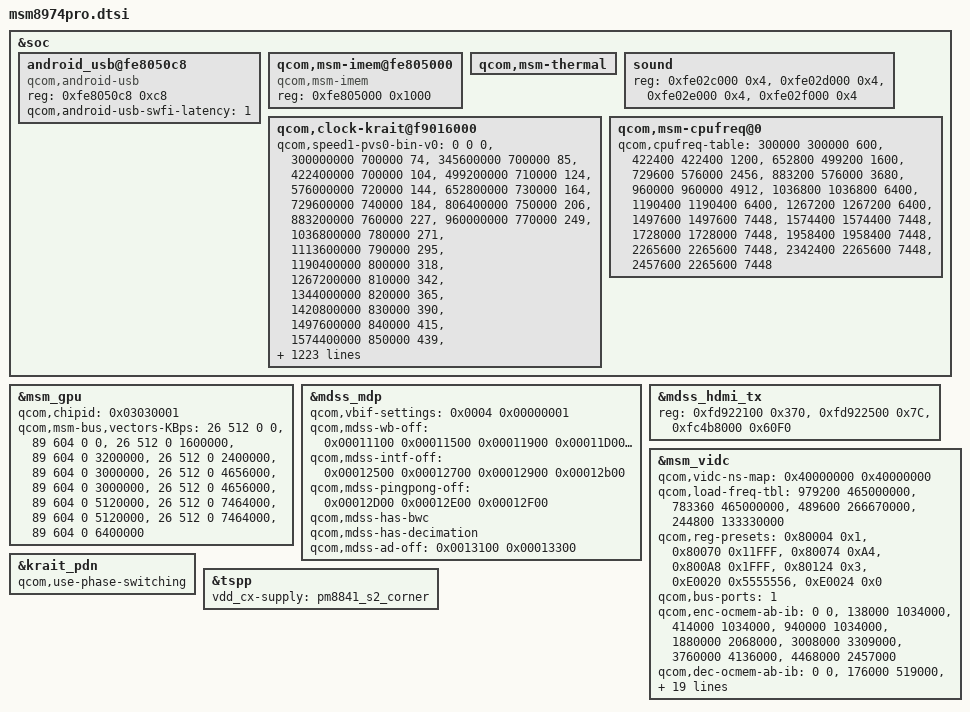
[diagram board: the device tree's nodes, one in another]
/* Copyright (c) 2013, The Linux Foundation. All rights reserved.
 *
 * This program is free software; you can redistribute it and/or modify
 * it under the terms of the GNU General Public License version 2 and
 * only version 2 as published by the Free Software Foundation.
 *
 * This program is distributed in the hope that it will be useful,
 * but WITHOUT ANY WARRANTY; without even the implied warranty of
 * MERCHANTABILITY or FITNESS FOR A PARTICULAR PURPOSE.  See the
 * GNU General Public License for more details.
 */

/*
 * As a general rule, only version-specific property overrides should be placed
 * inside this file. However, device definitions should be placed inside the
 * msm8974.dtsi file.
 */

/include/ "msm8974.dtsi"
/include/ "msm8974-v2-iommu.dtsi"
/include/ "msm8974-v2-iommu-domains.dtsi"
/include/ "msm8974-v2-pm.dtsi"

&soc {
	android_usb@fe8050c8 {
		compatible = "qcom,android-usb";
		reg = <0xfe8050c8 0xc8>;
		qcom,android-usb-swfi-latency = <1>;
	};

	qcom,msm-imem@fe805000 {
		compatible = "qcom,msm-imem";
		reg = <0xfe805000 0x1000>; /* Address and size of IMEM */
	};

	qcom,msm-thermal {
		/delete-property/ qcom,pmic-sw-mode-temp;
		/delete-property/ qcom,pmic-sw-mode-temp-hysteresis;
		/delete-property/ qcom,pmic-sw-mode-regs;
	};

	sound {
		reg = <0xfe02c000 0x4>,
		      <0xfe02d000 0x4>,
		      <0xfe02e000 0x4>,
		      <0xfe02f000 0x4>;
		reg-names = "lpaif_pri_mode_muxsel",
			    "lpaif_sec_mode_muxsel",
			    "lpaif_tert_mode_muxsel",
			    "lpaif_quat_mode_muxsel";
	};

	qcom,clock-krait@f9016000 {
		qcom,speed1-pvs0-bin-v0 =
			<          0       0    0 >,
			<  300000000  700000   74 >,
			<  345600000  700000   85 >,
			<  422400000  700000  104 >,
			<  499200000  710000  124 >,
			<  576000000  720000  144 >,
			<  652800000  730000  164 >,
			<  729600000  740000  184 >,
			<  806400000  750000  206 >,
			<  883200000  760000  227 >,
			<  960000000  770000  249 >,
			< 1036800000  780000  271 >,
			< 1113600000  790000  295 >,
			< 1190400000  800000  318 >,
			< 1267200000  810000  342 >,
			< 1344000000  820000  365 >,
			< 1420800000  830000  390 >,
			< 1497600000  840000  415 >,
			< 1574400000  850000  439 >,
			< 1651200000  865000  465 >,
			< 1728000000  880000  493 >,
			< 1804800000  895000  521 >,
			< 1881600000  910000  549 >,
			< 1958400000  925000  579 >,
			< 2035200000  940000  608 >,
			< 2112000000  955000  638 >,
			< 2150400000  970000  667 >,
			< 2188800000  970000  667 >,
			< 2265600000  980000  700 >,
			< 2342400000  990000  734 >,
			< 2419200000 1015000  769 >,
			< 2457600000 1020000  785 >;

		qcom,speed1-pvs1-bin-v0 =
			<          0       0    0 >,
			<  300000000  700000   74 >,
			<  345600000  700000   85 >,
			<  422400000  700000  104 >,
			<  499200000  710000  124 >,
			<  576000000  720000  144 >,
			<  652800000  730000  164 >,
			<  729600000  740000  184 >,
			<  806400000  750000  206 >,
			<  883200000  760000  227 >,
			<  960000000  770000  249 >,
			< 1036800000  780000  271 >,
			< 1113600000  790000  295 >,
			< 1190400000  800000  318 >,
			< 1267200000  810000  342 >,
			< 1344000000  820000  365 >,
			< 1420800000  830000  390 >,
			< 1497600000  840000  415 >,
			< 1574400000  850000  439 >,
			< 1651200000  865000  465 >,
			< 1728000000  880000  493 >,
			< 1804800000  895000  521 >,
			< 1881600000  910000  549 >,
			< 1958400000  925000  579 >,
			< 2035200000  940000  608 >,
			< 2112000000  955000  638 >,
			< 2150400000  970000  667 >,
			< 2188800000  970000  667 >,
			< 2265600000  980000  700 >,
			< 2342400000  990000  734 >,
			< 2419200000 1015000  769 >,
			< 2457600000 1020000  785 >;

		qcom,speed1-pvs2-bin-v0 =
			<          0       0    0 >,
			<  300000000  700000   74 >,
			<  345600000  700000   85 >,
			<  422400000  700000  104 >,
			<  499200000  710000  124 >,
			<  576000000  720000  144 >,
			<  652800000  730000  164 >,
			<  729600000  740000  184 >,
			<  806400000  750000  206 >,
			<  883200000  760000  227 >,
			<  960000000  770000  249 >,
			< 1036800000  780000  271 >,
			< 1113600000  790000  295 >,
			< 1190400000  800000  318 >,
			< 1267200000  810000  342 >,
			< 1344000000  820000  365 >,
			< 1420800000  830000  390 >,
			< 1497600000  840000  415 >,
			< 1574400000  850000  439 >,
			< 1651200000  865000  465 >,
			< 1728000000  880000  493 >,
			< 1804800000  895000  521 >,
			< 1881600000  910000  549 >,
			< 1958400000  925000  579 >,
			< 2035200000  940000  608 >,
			< 2112000000  955000  638 >,
			< 2150400000  970000  667 >,
			< 2188800000  970000  667 >,
			< 2265600000  980000  700 >,
			< 2342400000  990000  734 >,
			< 2419200000 1015000  769 >,
			< 2457600000 1020000  785 >;

		qcom,speed1-pvs3-bin-v0 =
			<          0       0    0 >,
			<  300000000  700000   74 >,
			<  345600000  700000   85 >,
			<  422400000  700000  104 >,
			<  499200000  710000  124 >,
			<  576000000  720000  144 >,
			<  652800000  730000  164 >,
			<  729600000  740000  184 >,
			<  806400000  750000  206 >,
			<  883200000  760000  227 >,
			<  960000000  770000  249 >,
			< 1036800000  780000  271 >,
			< 1113600000  790000  295 >,
			< 1190400000  800000  318 >,
			< 1267200000  810000  342 >,
			< 1344000000  820000  365 >,
			< 1420800000  830000  390 >,
			< 1497600000  840000  415 >,
			< 1574400000  850000  439 >,
			< 1651200000  865000  465 >,
			< 1728000000  880000  493 >,
			< 1804800000  895000  521 >,
			< 1881600000  910000  549 >,
			< 1958400000  925000  579 >,
			< 2035200000  940000  608 >,
			< 2112000000  955000  638 >,
			< 2150400000  970000  667 >,
			< 2188800000  970000  667 >,
			< 2265600000  980000  700 >,
			< 2342400000  990000  734 >,
			< 2419200000 1015000  769 >,
			< 2457600000 1020000  785 >;

		qcom,speed1-pvs4-bin-v0 =
			<          0       0    0 >,
			<  300000000  700000   74 >,
			<  345600000  700000   85 >,
			<  422400000  700000  104 >,
			<  499200000  710000  124 >,
			<  576000000  720000  144 >,
			<  652800000  730000  164 >,
			<  729600000  740000  184 >,
			<  806400000  750000  206 >,
			<  883200000  760000  227 >,
			<  960000000  770000  249 >,
			< 1036800000  780000  271 >,
			< 1113600000  790000  295 >,
			< 1190400000  800000  318 >,
			< 1267200000  810000  342 >,
			< 1344000000  820000  365 >,
			< 1420800000  830000  390 >,
			< 1497600000  840000  415 >,
			< 1574400000  850000  439 >,
			< 1651200000  865000  465 >,
			< 1728000000  880000  493 >,
			< 1804800000  895000  521 >,
			< 1881600000  910000  549 >,
			< 1958400000  925000  579 >,
			< 2035200000  940000  608 >,
			< 2112000000  955000  638 >,
			< 2150400000  970000  667 >,
			< 2188800000  970000  667 >,
			< 2265600000  980000  700 >,
			< 2342400000  990000  734 >,
			< 2419200000 1015000  769 >,
			< 2457600000 1020000  785 >;

		qcom,speed1-pvs5-bin-v0 =
			<          0       0    0 >,
			<  300000000  700000   74 >,
			<  345600000  700000   85 >,
			<  422400000  700000  104 >,
			<  499200000  710000  124 >,
			<  576000000  720000  144 >,
			<  652800000  730000  164 >,
			<  729600000  740000  184 >,
			<  806400000  750000  206 >,
			<  883200000  760000  227 >,
			<  960000000  770000  249 >,
			< 1036800000  780000  271 >,
			< 1113600000  790000  295 >,
			< 1190400000  800000  318 >,
			< 1267200000  810000  342 >,
			< 1344000000  820000  365 >,
			< 1420800000  830000  390 >,
			< 1497600000  840000  415 >,
			< 1574400000  850000  439 >,
			< 1651200000  865000  465 >,
			< 1728000000  880000  493 >,
			< 1804800000  895000  521 >,
			< 1881600000  910000  549 >,
			< 1958400000  925000  579 >,
			< 2035200000  940000  608 >,
			< 2112000000  955000  638 >,
			< 2150400000  970000  667 >,
			< 2188800000  970000  667 >,
			< 2265600000  980000  700 >,
			< 2342400000  990000  734 >,
			< 2419200000 1015000  769 >,
			< 2457600000 1020000  785 >;

		qcom,speed1-pvs6-bin-v0 =
			<          0       0    0 >,
			<  300000000  700000   74 >,
			<  345600000  700000   85 >,
			<  422400000  700000  104 >,
			<  499200000  710000  124 >,
			<  576000000  720000  144 >,
			<  652800000  730000  164 >,
			<  729600000  740000  184 >,
			<  806400000  750000  206 >,
			<  883200000  760000  227 >,
			<  960000000  770000  249 >,
			< 1036800000  780000  271 >,
			< 1113600000  790000  295 >,
			< 1190400000  800000  318 >,
			< 1267200000  810000  342 >,
			< 1344000000  820000  365 >,
			< 1420800000  830000  390 >,
			< 1497600000  840000  415 >,
			< 1574400000  850000  439 >,
			< 1651200000  865000  465 >,
			< 1728000000  880000  493 >,
			< 1804800000  895000  521 >,
			< 1881600000  910000  549 >,
			< 1958400000  925000  579 >,
			< 2035200000  940000  608 >,
			< 2112000000  955000  638 >,
			< 2150400000  970000  667 >,
			< 2188800000  970000  667 >,
			< 2265600000  980000  700 >,
			< 2342400000  990000  734 >,
			< 2419200000 1015000  769 >,
			< 2457600000 1020000  785 >;

		qcom,speed3-pvs0-bin-v0 =
			<          0       0    0 >,
			<  300000000  800000   76 >,
			<  345600000  800000   87 >,
			<  422400000  800000  106 >,
			<  499200000  800000  125 >,
			<  576000000  800000  145 >,
			<  652800000  810000  165 >,
			<  729600000  820000  186 >,
			<  806400000  830000  208 >,
			<  883200000  840000  229 >,
			<  960000000  850000  251 >,
			< 1036800000  860000  273 >,
			< 1113600000  870000  296 >,
			< 1190400000  880000  319 >,
			< 1267200000  890000  342 >,
			< 1344000000  900000  365 >,
			< 1420800000  910000  390 >,
			< 1497600000  920000  415 >,
			< 1574400000  930000  439 >,
			< 1651200000  945000  465 >,
			< 1728000000  960000  493 >,
			< 1804800000  975000  521 >,
			< 1881600000  990000  549 >,
			< 1958400000 1005000  579 >,
			< 2035200000 1020000  608 >,
			< 2112000000 1035000  638 >,
			< 2150400000 1050000  667 >,
			< 2188800000 1050000  667 >,
			< 2265600000 1065000  700 >,
			< 2342400000 1080000  734 >,
			< 2419200000 1095000  769 >,
			< 2457600000 1100000  785 >;

		qcom,speed3-pvs1-bin-v0 =
			<          0       0    0 >,
			<  300000000  800000   76 >,
			<  345600000  800000   87 >,
			<  422400000  800000  106 >,
			<  499200000  800000  125 >,
			<  576000000  800000  145 >,
			<  652800000  800000  165 >,
			<  729600000  800000  186 >,
			<  806400000  805000  208 >,
			<  883200000  815000  229 >,
			<  960000000  825000  251 >,
			< 1036800000  835000  273 >,
			< 1113600000  845000  296 >,
			< 1190400000  855000  319 >,
			< 1267200000  865000  342 >,
			< 1344000000  875000  365 >,
			< 1420800000  885000  390 >,
			< 1497600000  895000  415 >,
			< 1574400000  905000  439 >,
			< 1651200000  920000  465 >,
			< 1728000000  935000  493 >,
			< 1804800000  950000  521 >,
			< 1881600000  965000  549 >,
			< 1958400000  980000  579 >,
			< 2035200000  995000  608 >,
			< 2112000000 1010000  638 >,
			< 2150400000 1025000  667 >,
			< 2188800000 1025000  667 >,
			< 2265600000 1040000  700 >,
			< 2342400000 1055000  734 >,
			< 2419200000 1070000  769 >,
			< 2457600000 1075000  785 >;

		qcom,speed3-pvs2-bin-v0 =
			<          0       0    0 >,
			<  300000000  775000   76 >,
			<  345600000  775000   87 >,
			<  422400000  775000  106 >,
			<  499200000  775000  125 >,
			<  576000000  775000  145 >,
			<  652800000  775000  165 >,
			<  729600000  775000  186 >,
			<  806400000  780000  208 >,
			<  883200000  790000  229 >,
			<  960000000  800000  251 >,
			< 1036800000  810000  273 >,
			< 1113600000  820000  296 >,
			< 1190400000  830000  319 >,
			< 1267200000  840000  342 >,
			< 1344000000  850000  365 >,
			< 1420800000  860000  390 >,
			< 1497600000  870000  415 >,
			< 1574400000  880000  439 >,
			< 1651200000  895000  465 >,
			< 1728000000  910000  493 >,
			< 1804800000  925000  521 >,
			< 1881600000  940000  549 >,
			< 1958400000  955000  579 >,
			< 2035200000  970000  608 >,
			< 2112000000  985000  638 >,
			< 2150400000 1000000  667 >,
			< 2188800000 1000000  667 >,
			< 2265600000 1015000  700 >,
			< 2342400000 1030000  734 >,
			< 2419200000 1045000  769 >,
			< 2457600000 1050000  785 >;

		qcom,speed3-pvs3-bin-v0 =
			<          0       0    0 >,
			<  300000000  775000   76 >,
			<  345600000  775000   87 >,
			<  422400000  775000  106 >,
			<  499200000  775000  125 >,
			<  576000000  775000  145 >,
			<  652800000  775000  165 >,
			<  729600000  775000  186 >,
			<  806400000  775000  208 >,
			<  883200000  775000  229 >,
			<  960000000  780000  251 >,
			< 1036800000  785000  273 >,
			< 1113600000  795000  296 >,
			< 1190400000  805000  319 >,
			< 1267200000  815000  342 >,
			< 1344000000  825000  365 >,
			< 1420800000  835000  390 >,
			< 1497600000  845000  415 >,
			< 1574400000  855000  439 >,
			< 1651200000  870000  465 >,
			< 1728000000  885000  493 >,
			< 1804800000  900000  521 >,
			< 1881600000  915000  549 >,
			< 1958400000  930000  579 >,
			< 2035200000  945000  608 >,
			< 2112000000  960000  638 >,
			< 2150400000  975000  667 >,
			< 2188800000  975000  667 >,
			< 2265600000  990000  700 >,
			< 2342400000 1005000  734 >,
			< 2419200000 1020000  769 >,
			< 2457600000 1025000  785 >;

		qcom,speed3-pvs4-bin-v0 =
			<          0       0    0 >,
			<  300000000  775000   76 >,
			<  345600000  775000   87 >,
			<  422400000  775000  106 >,
			<  499200000  775000  125 >,
			<  576000000  775000  145 >,
			<  652800000  775000  165 >,
			<  729600000  775000  186 >,
			<  806400000  775000  208 >,
			<  883200000  775000  229 >,
			<  960000000  775000  251 >,
			< 1036800000  775000  273 >,
			< 1113600000  775000  296 >,
			< 1190400000  780000  319 >,
			< 1267200000  790000  342 >,
			< 1344000000  800000  365 >,
			< 1420800000  810000  390 >,
			< 1497600000  820000  415 >,
			< 1574400000  830000  439 >,
			< 1651200000  845000  465 >,
			< 1728000000  860000  493 >,
			< 1804800000  875000  521 >,
			< 1881600000  890000  549 >,
			< 1958400000  905000  579 >,
			< 2035200000  920000  608 >,
			< 2112000000  935000  638 >,
			< 2150400000  950000  667 >,
			< 2188800000  950000  667 >,
			< 2265600000  965000  700 >,
			< 2342400000  980000  734 >,
			< 2419200000  995000  769 >,
			< 2457600000 1000000  785 >;

		qcom,speed3-pvs5-bin-v0 =
			<          0       0    0 >,
			<  300000000  750000   76 >,
			<  345600000  750000   87 >,
			<  422400000  750000  106 >,
			<  499200000  750000  125 >,
			<  576000000  750000  145 >,
			<  652800000  750000  165 >,
			<  729600000  750000  186 >,
			<  806400000  750000  208 >,
			<  883200000  750000  229 >,
			<  960000000  750000  251 >,
			< 1036800000  750000  273 >,
			< 1113600000  750000  296 >,
			< 1190400000  760000  319 >,
			< 1267200000  770000  342 >,
			< 1344000000  780000  365 >,
			< 1420800000  790000  390 >,
			< 1497600000  800000  415 >,
			< 1574400000  810000  439 >,
			< 1651200000  820000  465 >,
			< 1728000000  835000  493 >,
			< 1804800000  850000  521 >,
			< 1881600000  865000  549 >,
			< 1958400000  880000  579 >,
			< 2035200000  895000  608 >,
			< 2112000000  910000  638 >,
			< 2150400000  925000  667 >,
			< 2188800000  925000  667 >,
			< 2265600000  940000  700 >,
			< 2342400000  955000  734 >,
			< 2419200000  970000  769 >,
			< 2457600000  975000  785 >;

		qcom,speed3-pvs6-bin-v0 =
			<          0       0    0 >,
			<  300000000  750000   76 >,
			<  345600000  750000   87 >,
			<  422400000  750000  106 >,
			<  499200000  750000  125 >,
			<  576000000  750000  145 >,
			<  652800000  750000  165 >,
			<  729600000  750000  186 >,
			<  806400000  750000  208 >,
			<  883200000  750000  229 >,
			<  960000000  750000  251 >,
			< 1036800000  750000  273 >,
			< 1113600000  750000  296 >,
			< 1190400000  750000  319 >,
			< 1267200000  755000  342 >,
			< 1344000000  765000  365 >,
			< 1420800000  775000  390 >,
			< 1497600000  785000  415 >,
			< 1574400000  795000  439 >,
			< 1651200000  805000  465 >,
			< 1728000000  815000  493 >,
			< 1804800000  825000  521 >,
			< 1881600000  840000  549 >,
			< 1958400000  855000  579 >,
			< 2035200000  870000  608 >,
			< 2112000000  885000  638 >,
			< 2150400000  900000  667 >,
			< 2188800000  900000  667 >,
			< 2265600000  915000  700 >,
			< 2342400000  930000  734 >,
			< 2419200000  945000  769 >,
			< 2457600000  950000  785 >;

		qcom,speed1-pvs0-bin-v1 =
			<          0       0    0 >,
			<  300000000  700000   74 >,
			<  345600000  700000   85 >,
			<  422400000  700000  104 >,
			<  499200000  710000  124 >,
			<  576000000  720000  144 >,
			<  652800000  730000  164 >,
			<  729600000  740000  184 >,
			<  806400000  750000  206 >,
			<  883200000  760000  227 >,
			<  960000000  770000  249 >,
			< 1036800000  780000  271 >,
			< 1113600000  790000  295 >,
			< 1190400000  800000  318 >,
			< 1267200000  810000  342 >,
			< 1344000000  820000  365 >,
			< 1420800000  830000  390 >,
			< 1497600000  840000  415 >,
			< 1574400000  850000  439 >,
			< 1651200000  865000  465 >,
			< 1728000000  880000  493 >,
			< 1804800000  895000  521 >,
			< 1881600000  910000  549 >,
			< 1958400000  925000  579 >,
			< 2035200000  940000  608 >,
			< 2112000000  955000  638 >,
			< 2150400000  970000  667 >,
			< 2188800000  970000  667 >,
			< 2265600000  980000  700 >,
			< 2342400000  990000  734 >,
			< 2419200000 1015000  769 >,
			< 2457600000 1020000  785 >;

		qcom,speed1-pvs1-bin-v1 =
			<          0       0    0 >,
			<  300000000  700000   74 >,
			<  345600000  700000   85 >,
			<  422400000  700000  104 >,
			<  499200000  710000  124 >,
			<  576000000  720000  144 >,
			<  652800000  730000  164 >,
			<  729600000  740000  184 >,
			<  806400000  750000  206 >,
			<  883200000  760000  227 >,
			<  960000000  770000  249 >,
			< 1036800000  780000  271 >,
			< 1113600000  790000  295 >,
			< 1190400000  800000  318 >,
			< 1267200000  810000  342 >,
			< 1344000000  820000  365 >,
			< 1420800000  830000  390 >,
			< 1497600000  840000  415 >,
			< 1574400000  850000  439 >,
			< 1651200000  865000  465 >,
			< 1728000000  880000  493 >,
			< 1804800000  895000  521 >,
			< 1881600000  910000  549 >,
			< 1958400000  925000  579 >,
			< 2035200000  940000  608 >,
			< 2112000000  955000  638 >,
			< 2150400000  970000  667 >,
			< 2188800000  970000  667 >,
			< 2265600000  980000  700 >,
			< 2342400000  990000  734 >,
			< 2419200000 1015000  769 >,
			< 2457600000 1020000  785 >;

		qcom,speed1-pvs2-bin-v1 =
			<          0       0    0 >,
			<  300000000  700000   74 >,
			<  345600000  700000   85 >,
			<  422400000  700000  104 >,
			<  499200000  710000  124 >,
			<  576000000  720000  144 >,
			<  652800000  730000  164 >,
			<  729600000  740000  184 >,
			<  806400000  750000  206 >,
			<  883200000  760000  227 >,
			<  960000000  770000  249 >,
			< 1036800000  780000  271 >,
			< 1113600000  790000  295 >,
			< 1190400000  800000  318 >,
			< 1267200000  810000  342 >,
			< 1344000000  820000  365 >,
			< 1420800000  830000  390 >,
			< 1497600000  840000  415 >,
			< 1574400000  850000  439 >,
			< 1651200000  865000  465 >,
			< 1728000000  880000  493 >,
			< 1804800000  895000  521 >,
			< 1881600000  910000  549 >,
			< 1958400000  925000  579 >,
			< 2035200000  940000  608 >,
			< 2112000000  955000  638 >,
			< 2150400000  970000  667 >,
			< 2188800000  970000  667 >,
			< 2265600000  980000  700 >,
			< 2342400000  990000  734 >,
			< 2419200000 1015000  769 >,
			< 2457600000 1020000  785 >;

		qcom,speed1-pvs3-bin-v1 =
			<          0       0    0 >,
			<  300000000  700000   74 >,
			<  345600000  700000   85 >,
			<  422400000  700000  104 >,
			<  499200000  710000  124 >,
			<  576000000  720000  144 >,
			<  652800000  730000  164 >,
			<  729600000  740000  184 >,
			<  806400000  750000  206 >,
			<  883200000  760000  227 >,
			<  960000000  770000  249 >,
			< 1036800000  780000  271 >,
			< 1113600000  790000  295 >,
			< 1190400000  800000  318 >,
			< 1267200000  810000  342 >,
			< 1344000000  820000  365 >,
			< 1420800000  830000  390 >,
			< 1497600000  840000  415 >,
			< 1574400000  850000  439 >,
			< 1651200000  865000  465 >,
			< 1728000000  880000  493 >,
			< 1804800000  895000  521 >,
			< 1881600000  910000  549 >,
			< 1958400000  925000  579 >,
			< 2035200000  940000  608 >,
			< 2112000000  955000  638 >,
			< 2150400000  970000  667 >,
			< 2188800000  970000  667 >,
			< 2265600000  980000  700 >,
			< 2342400000  990000  734 >,
			< 2419200000 1015000  769 >,
			< 2457600000 1020000  785 >;

		qcom,speed1-pvs4-bin-v1 =
			<          0       0    0 >,
			<  300000000  700000   74 >,
			<  345600000  700000   85 >,
			<  422400000  700000  104 >,
			<  499200000  710000  124 >,
			<  576000000  720000  144 >,
			<  652800000  730000  164 >,
			<  729600000  740000  184 >,
			<  806400000  750000  206 >,
			<  883200000  760000  227 >,
			<  960000000  770000  249 >,
			< 1036800000  780000  271 >,
			< 1113600000  790000  295 >,
			< 1190400000  800000  318 >,
			< 1267200000  810000  342 >,
			< 1344000000  820000  365 >,
			< 1420800000  830000  390 >,
			< 1497600000  840000  415 >,
			< 1574400000  850000  439 >,
			< 1651200000  865000  465 >,
			< 1728000000  880000  493 >,
			< 1804800000  895000  521 >,
			< 1881600000  910000  549 >,
			< 1958400000  925000  579 >,
			< 2035200000  940000  608 >,
			< 2112000000  955000  638 >,
			< 2150400000  970000  667 >,
			< 2188800000  970000  667 >,
			< 2265600000  980000  700 >,
			< 2342400000  990000  734 >,
			< 2419200000 1015000  769 >,
			< 2457600000 1020000  785 >;

		qcom,speed1-pvs5-bin-v1 =
			<          0       0    0 >,
			<  300000000  700000   74 >,
			<  345600000  700000   85 >,
			<  422400000  700000  104 >,
			<  499200000  710000  124 >,
			<  576000000  720000  144 >,
			<  652800000  730000  164 >,
			<  729600000  740000  184 >,
			<  806400000  750000  206 >,
			<  883200000  760000  227 >,
			<  960000000  770000  249 >,
			< 1036800000  780000  271 >,
			< 1113600000  790000  295 >,
			< 1190400000  800000  318 >,
			< 1267200000  810000  342 >,
			< 1344000000  820000  365 >,
			< 1420800000  830000  390 >,
			< 1497600000  840000  415 >,
			< 1574400000  850000  439 >,
			< 1651200000  865000  465 >,
			< 1728000000  880000  493 >,
			< 1804800000  895000  521 >,
			< 1881600000  910000  549 >,
			< 1958400000  925000  579 >,
			< 2035200000  940000  608 >,
			< 2112000000  955000  638 >,
			< 2150400000  970000  667 >,
			< 2188800000  970000  667 >,
			< 2265600000  980000  700 >,
			< 2342400000  990000  734 >,
			< 2419200000 1015000  769 >,
			< 2457600000 1020000  785 >;

		qcom,speed1-pvs6-bin-v1 =
			<          0       0    0 >,
			<  300000000  700000   74 >,
			<  345600000  700000   85 >,
			<  422400000  700000  104 >,
			<  499200000  710000  124 >,
			<  576000000  720000  144 >,
			<  652800000  730000  164 >,
			<  729600000  740000  184 >,
			<  806400000  750000  206 >,
			<  883200000  760000  227 >,
			<  960000000  770000  249 >,
			< 1036800000  780000  271 >,
			< 1113600000  790000  295 >,
			< 1190400000  800000  318 >,
			< 1267200000  810000  342 >,
			< 1344000000  820000  365 >,
			< 1420800000  830000  390 >,
			< 1497600000  840000  415 >,
			< 1574400000  850000  439 >,
			< 1651200000  865000  465 >,
			< 1728000000  880000  493 >,
			< 1804800000  895000  521 >,
			< 1881600000  910000  549 >,
			< 1958400000  925000  579 >,
			< 2035200000  940000  608 >,
			< 2112000000  955000  638 >,
			< 2150400000  970000  667 >,
			< 2188800000  970000  667 >,
			< 2265600000  980000  700 >,
			< 2342400000  990000  734 >,
			< 2419200000 1015000  769 >,
			< 2457600000 1020000  785 >;

		qcom,speed1-pvs7-bin-v1 =
			<          0       0    0 >,
			<  300000000  700000   74 >,
			<  345600000  700000   85 >,
			<  422400000  700000  104 >,
			<  499200000  710000  124 >,
			<  576000000  720000  144 >,
			<  652800000  730000  164 >,
			<  729600000  740000  184 >,
			<  806400000  750000  206 >,
			<  883200000  760000  227 >,
			<  960000000  770000  249 >,
			< 1036800000  780000  271 >,
			< 1113600000  790000  295 >,
			< 1190400000  800000  318 >,
			< 1267200000  810000  342 >,
			< 1344000000  820000  365 >,
			< 1420800000  830000  390 >,
			< 1497600000  840000  415 >,
			< 1574400000  850000  439 >,
			< 1651200000  865000  465 >,
			< 1728000000  880000  493 >,
			< 1804800000  895000  521 >,
			< 1881600000  910000  549 >,
			< 1958400000  925000  579 >,
			< 2035200000  940000  608 >,
			< 2112000000  955000  638 >,
			< 2150400000  970000  667 >,
			< 2188800000  970000  667 >,
			< 2265600000  980000  700 >,
			< 2342400000  990000  734 >,
			< 2419200000 1015000  769 >,
			< 2457600000 1020000  785 >;

		qcom,speed1-pvs8-bin-v1 =
			<          0       0    0 >,
			<  300000000  700000   74 >,
			<  345600000  700000   85 >,
			<  422400000  700000  104 >,
			<  499200000  710000  124 >,
			<  576000000  720000  144 >,
			<  652800000  730000  164 >,
			<  729600000  740000  184 >,
			<  806400000  750000  206 >,
			<  883200000  760000  227 >,
			<  960000000  770000  249 >,
			< 1036800000  780000  271 >,
			< 1113600000  790000  295 >,
			< 1190400000  800000  318 >,
			< 1267200000  810000  342 >,
			< 1344000000  820000  365 >,
			< 1420800000  830000  390 >,
			< 1497600000  840000  415 >,
			< 1574400000  850000  439 >,
			< 1651200000  865000  465 >,
			< 1728000000  880000  493 >,
			< 1804800000  895000  521 >,
			< 1881600000  910000  549 >,
			< 1958400000  925000  579 >,
			< 2035200000  940000  608 >,
			< 2112000000  955000  638 >,
			< 2150400000  970000  667 >,
			< 2188800000  970000  667 >,
			< 2265600000  980000  700 >,
			< 2342400000  990000  734 >,
			< 2419200000 1015000  769 >,
			< 2457600000 1020000  785 >;

		qcom,speed1-pvs9-bin-v1 =
			<          0       0    0 >,
			<  300000000  700000   74 >,
			<  345600000  700000   85 >,
			<  422400000  700000  104 >,
			<  499200000  710000  124 >,
			<  576000000  720000  144 >,
			<  652800000  730000  164 >,
			<  729600000  740000  184 >,
			<  806400000  750000  206 >,
			<  883200000  760000  227 >,
			<  960000000  770000  249 >,
			< 1036800000  780000  271 >,
			< 1113600000  790000  295 >,
			< 1190400000  800000  318 >,
			< 1267200000  810000  342 >,
			< 1344000000  820000  365 >,
			< 1420800000  830000  390 >,
			< 1497600000  840000  415 >,
			< 1574400000  850000  439 >,
			< 1651200000  865000  465 >,
			< 1728000000  880000  493 >,
			< 1804800000  895000  521 >,
			< 1881600000  910000  549 >,
			< 1958400000  925000  579 >,
			< 2035200000  940000  608 >,
			< 2112000000  955000  638 >,
			< 2150400000  970000  667 >,
			< 2188800000  970000  667 >,
			< 2265600000  980000  700 >,
			< 2342400000  990000  734 >,
			< 2419200000 1015000  769 >,
			< 2457600000 1020000  785 >;

		qcom,speed1-pvs10-bin-v1 =
			<          0       0    0 >,
			<  300000000  700000   74 >,
			<  345600000  700000   85 >,
			<  422400000  700000  104 >,
			<  499200000  710000  124 >,
			<  576000000  720000  144 >,
			<  652800000  730000  164 >,
			<  729600000  740000  184 >,
			<  806400000  750000  206 >,
			<  883200000  760000  227 >,
			<  960000000  770000  249 >,
			< 1036800000  780000  271 >,
			< 1113600000  790000  295 >,
			< 1190400000  800000  318 >,
			< 1267200000  810000  342 >,
			< 1344000000  820000  365 >,
			< 1420800000  830000  390 >,
			< 1497600000  840000  415 >,
			< 1574400000  850000  439 >,
			< 1651200000  865000  465 >,
			< 1728000000  880000  493 >,
			< 1804800000  895000  521 >,
			< 1881600000  910000  549 >,
			< 1958400000  925000  579 >,
			< 2035200000  940000  608 >,
			< 2112000000  955000  638 >,
			< 2150400000  970000  667 >,
			< 2188800000  970000  667 >,
			< 2265600000  980000  700 >,
			< 2342400000  990000  734 >,
			< 2419200000 1015000  769 >,
			< 2457600000 1020000  785 >;

		qcom,speed1-pvs11-bin-v1 =
			<          0       0    0 >,
			<  300000000  700000   74 >,
			<  345600000  700000   85 >,
			<  422400000  700000  104 >,
			<  499200000  710000  124 >,
			<  576000000  720000  144 >,
			<  652800000  730000  164 >,
			<  729600000  740000  184 >,
			<  806400000  750000  206 >,
			<  883200000  760000  227 >,
			<  960000000  770000  249 >,
			< 1036800000  780000  271 >,
			< 1113600000  790000  295 >,
			< 1190400000  800000  318 >,
			< 1267200000  810000  342 >,
			< 1344000000  820000  365 >,
			< 1420800000  830000  390 >,
			< 1497600000  840000  415 >,
			< 1574400000  850000  439 >,
			< 1651200000  865000  465 >,
			< 1728000000  880000  493 >,
			< 1804800000  895000  521 >,
			< 1881600000  910000  549 >,
			< 1958400000  925000  579 >,
			< 2035200000  940000  608 >,
			< 2112000000  955000  638 >,
			< 2150400000  970000  667 >,
			< 2188800000  970000  667 >,
			< 2265600000  980000  700 >,
			< 2342400000  990000  734 >,
			< 2419200000 1015000  769 >,
			< 2457600000 1020000  785 >;

		qcom,speed1-pvs12-bin-v1 =
			<          0       0    0 >,
			<  300000000  700000   74 >,
			<  345600000  700000   85 >,
			<  422400000  700000  104 >,
			<  499200000  710000  124 >,
			<  576000000  720000  144 >,
			<  652800000  730000  164 >,
			<  729600000  740000  184 >,
			<  806400000  750000  206 >,
			<  883200000  760000  227 >,
			<  960000000  770000  249 >,
			< 1036800000  780000  271 >,
			< 1113600000  790000  295 >,
			< 1190400000  800000  318 >,
			< 1267200000  810000  342 >,
			< 1344000000  820000  365 >,
			< 1420800000  830000  390 >,
			< 1497600000  840000  415 >,
			< 1574400000  850000  439 >,
			< 1651200000  865000  465 >,
			< 1728000000  880000  493 >,
			< 1804800000  895000  521 >,
			< 1881600000  910000  549 >,
			< 1958400000  925000  579 >,
			< 2035200000  940000  608 >,
			< 2112000000  955000  638 >,
			< 2150400000  970000  667 >,
			< 2188800000  970000  667 >,
			< 2265600000  980000  700 >,
			< 2342400000  990000  734 >,
			< 2419200000 1015000  769 >,
			< 2457600000 1020000  785 >;

		qcom,speed1-pvs13-bin-v1 =
			<          0       0    0 >,
			<  300000000  700000   74 >,
			<  345600000  700000   85 >,
			<  422400000  700000  104 >,
			<  499200000  710000  124 >,
			<  576000000  720000  144 >,
			<  652800000  730000  164 >,
			<  729600000  740000  184 >,
			<  806400000  750000  206 >,
			<  883200000  760000  227 >,
			<  960000000  770000  249 >,
			< 1036800000  780000  271 >,
			< 1113600000  790000  295 >,
			< 1190400000  800000  318 >,
			< 1267200000  810000  342 >,
			< 1344000000  820000  365 >,
			< 1420800000  830000  390 >,
			< 1497600000  840000  415 >,
			< 1574400000  850000  439 >,
			< 1651200000  865000  465 >,
			< 1728000000  880000  493 >,
			< 1804800000  895000  521 >,
			< 1881600000  910000  549 >,
			< 1958400000  925000  579 >,
			< 2035200000  940000  608 >,
			< 2112000000  955000  638 >,
			< 2150400000  970000  667 >,
			< 2188800000  970000  667 >,
			< 2265600000  980000  700 >,
			< 2342400000  990000  734 >,
			< 2419200000 1015000  769 >,
			< 2457600000 1020000  785 >;

		qcom,speed1-pvs14-bin-v1 =
			<          0       0    0 >,
			<  300000000  700000   74 >,
			<  345600000  700000   85 >,
			<  422400000  700000  104 >,
			<  499200000  710000  124 >,
			<  576000000  720000  144 >,
			<  652800000  730000  164 >,
			<  729600000  740000  184 >,
			<  806400000  750000  206 >,
			<  883200000  760000  227 >,
			<  960000000  770000  249 >,
			< 1036800000  780000  271 >,
			< 1113600000  790000  295 >,
			< 1190400000  800000  318 >,
			< 1267200000  810000  342 >,
			< 1344000000  820000  365 >,
			< 1420800000  830000  390 >,
			< 1497600000  840000  415 >,
			< 1574400000  850000  439 >,
			< 1651200000  865000  465 >,
			< 1728000000  880000  493 >,
			< 1804800000  895000  521 >,
			< 1881600000  910000  549 >,
			< 1958400000  925000  579 >,
			< 2035200000  940000  608 >,
			< 2112000000  955000  638 >,
			< 2150400000  970000  667 >,
			< 2188800000  970000  667 >,
			< 2265600000  980000  700 >,
			< 2342400000  990000  734 >,
			< 2419200000 1015000  769 >,
			< 2457600000 1020000  785 >;

		qcom,speed1-pvs15-bin-v1 =
			<          0       0    0 >,
			<  300000000  700000   74 >,
			<  345600000  700000   85 >,
			<  422400000  700000  104 >,
			<  499200000  710000  124 >,
			<  576000000  720000  144 >,
			<  652800000  730000  164 >,
			<  729600000  740000  184 >,
			<  806400000  750000  206 >,
			<  883200000  760000  227 >,
			<  960000000  770000  249 >,
			< 1036800000  780000  271 >,
			< 1113600000  790000  295 >,
			< 1190400000  800000  318 >,
			< 1267200000  810000  342 >,
			< 1344000000  820000  365 >,
			< 1420800000  830000  390 >,
			< 1497600000  840000  415 >,
			< 1574400000  850000  439 >,
			< 1651200000  865000  465 >,
			< 1728000000  880000  493 >,
			< 1804800000  895000  521 >,
			< 1881600000  910000  549 >,
			< 1958400000  925000  579 >,
			< 2035200000  940000  608 >,
			< 2112000000  955000  638 >,
			< 2150400000  970000  667 >,
			< 2188800000  970000  667 >,
			< 2265600000  980000  700 >,
			< 2342400000  990000  734 >,
			< 2419200000 1015000  769 >,
			< 2457600000 1020000  785 >;

		qcom,speed3-pvs0-bin-v1 =
			<          0       0    0 >,
			<  300000000  800000   76 >,
			<  345600000  800000   87 >,
			<  422400000  800000  106 >,
			<  499200000  810000  126 >,
			<  576000000  820000  147 >,
			<  652800000  830000  168 >,
			<  729600000  840000  189 >,
			<  806400000  850000  211 >,
			<  883200000  860000  233 >,
			<  960000000  870000  256 >,
			< 1036800000  880000  278 >,
			< 1113600000  890000  301 >,
			< 1190400000  900000  324 >,
			< 1267200000  910000  348 >,
			< 1344000000  920000  372 >,
			< 1420800000  930000  396 >,
			< 1497600000  940000  421 >,
			< 1574400000  950000  446 >,
			< 1651200000  965000  473 >,
			< 1728000000  980000  501 >,
			< 1804800000  995000  529 >,
			< 1881600000 1010000  558 >,
			< 1958400000 1025000  588 >,
			< 2035200000 1040000  617 >,
			< 2112000000 1055000  649 >,
			< 2150400000 1070000  682 >,
			< 2188800000 1070000  682 >,
			< 2265600000 1085000  716 >,
			< 2342400000 1100000  751 >,
			< 2419200000 1115000  786 >,
			< 2457600000 1120000  802 >;

		qcom,speed3-pvs1-bin-v1 =
			<          0       0    0 >,
			<  300000000  800000   76 >,
			<  345600000  800000   87 >,
			<  422400000  800000  106 >,
			<  499200000  800000  126 >,
			<  576000000  810000  147 >,
			<  652800000  820000  168 >,
			<  729600000  830000  189 >,
			<  806400000  840000  211 >,
			<  883200000  850000  233 >,
			<  960000000  860000  256 >,
			< 1036800000  870000  278 >,
			< 1113600000  880000  301 >,
			< 1190400000  890000  324 >,
			< 1267200000  900000  348 >,
			< 1344000000  910000  372 >,
			< 1420800000  920000  396 >,
			< 1497600000  930000  421 >,
			< 1574400000  940000  446 >,
			< 1651200000  955000  473 >,
			< 1728000000  970000  501 >,
			< 1804800000  985000  529 >,
			< 1881600000 1000000  558 >,
			< 1958400000 1015000  588 >,
			< 2035200000 1030000  617 >,
			< 2112000000 1045000  649 >,
			< 2150400000 1060000  682 >,
			< 2188800000 1060000  682 >,
			< 2265600000 1075000  716 >,
			< 2342400000 1090000  751 >,
			< 2419200000 1105000  786 >,
			< 2457600000 1110000  802 >;

		qcom,speed3-pvs2-bin-v1 =
			<          0       0    0 >,
			<  300000000  800000   76 >,
			<  345600000  800000   87 >,
			<  422400000  800000  106 >,
			<  499200000  800000  126 >,
			<  576000000  800000  147 >,
			<  652800000  810000  168 >,
			<  729600000  820000  189 >,
			<  806400000  830000  211 >,
			<  883200000  840000  233 >,
			<  960000000  850000  256 >,
			< 1036800000  860000  278 >,
			< 1113600000  870000  301 >,
			< 1190400000  880000  324 >,
			< 1267200000  890000  348 >,
			< 1344000000  900000  372 >,
			< 1420800000  910000  396 >,
			< 1497600000  920000  421 >,
			< 1574400000  930000  446 >,
			< 1651200000  945000  473 >,
			< 1728000000  960000  501 >,
			< 1804800000  975000  529 >,
			< 1881600000  990000  558 >,
			< 1958400000 1005000  588 >,
			< 2035200000 1020000  617 >,
			< 2112000000 1035000  649 >,
			< 2150400000 1050000  682 >,
			< 2188800000 1050000  682 >,
			< 2265600000 1065000  716 >,
			< 2342400000 1080000  751 >,
			< 2419200000 1095000  786 >,
			< 2457600000 1100000  802 >;

		qcom,speed3-pvs3-bin-v1 =
			<          0       0    0 >,
			<  300000000  800000   76 >,
			<  345600000  800000   87 >,
			<  422400000  800000  106 >,
			<  499200000  800000  126 >,
			<  576000000  800000  147 >,
			<  652800000  800000  168 >,
			<  729600000  810000  189 >,
			<  806400000  820000  211 >,
			<  883200000  830000  233 >,
			<  960000000  840000  256 >,
			< 1036800000  850000  278 >,
			< 1113600000  860000  301 >,
			< 1190400000  870000  324 >,
			< 1267200000  880000  348 >,
			< 1344000000  890000  372 >,
			< 1420800000  900000  396 >,
			< 1497600000  910000  421 >,
			< 1574400000  920000  446 >,
			< 1651200000  935000  473 >,
			< 1728000000  950000  501 >,
			< 1804800000  965000  529 >,
			< 1881600000  980000  558 >,
			< 1958400000  995000  588 >,
			< 2035200000 1010000  617 >,
			< 2112000000 1025000  649 >,
			< 2150400000 1040000  682 >,
			< 2188800000 1040000  682 >,
			< 2265600000 1055000  716 >,
			< 2342400000 1070000  751 >,
			< 2419200000 1085000  786 >,
			< 2457600000 1090000  802 >;

		qcom,speed3-pvs4-bin-v1 =
			<          0       0    0 >,
			<  300000000  800000   76 >,
			<  345600000  800000   87 >,
			<  422400000  800000  106 >,
			<  499200000  800000  126 >,
			<  576000000  800000  147 >,
			<  652800000  800000  168 >,
			<  729600000  800000  189 >,
			<  806400000  810000  211 >,
			<  883200000  820000  233 >,
			<  960000000  830000  256 >,
			< 1036800000  840000  278 >,
			< 1113600000  850000  301 >,
			< 1190400000  860000  324 >,
			< 1267200000  870000  348 >,
			< 1344000000  880000  372 >,
			< 1420800000  890000  396 >,
			< 1497600000  900000  421 >,
			< 1574400000  910000  446 >,
			< 1651200000  925000  473 >,
			< 1728000000  940000  501 >,
			< 1804800000  955000  529 >,
			< 1881600000  970000  558 >,
			< 1958400000  985000  588 >,
			< 2035200000 1000000  617 >,
			< 2112000000 1015000  649 >,
			< 2150400000 1030000  682 >,
			< 2188800000 1030000  682 >,
			< 2265600000 1045000  716 >,
			< 2342400000 1060000  751 >,
			< 2419200000 1075000  786 >,
			< 2457600000 1080000  802 >;

		qcom,speed3-pvs5-bin-v1 =
			<          0       0    0 >,
			<  300000000  800000   76 >,
			<  345600000  800000   87 >,
			<  422400000  800000  106 >,
			<  499200000  800000  126 >,
			<  576000000  800000  147 >,
			<  652800000  800000  168 >,
			<  729600000  800000  189 >,
			<  806400000  800000  211 >,
			<  883200000  810000  233 >,
			<  960000000  820000  256 >,
			< 1036800000  830000  278 >,
			< 1113600000  840000  301 >,
			< 1190400000  850000  324 >,
			< 1267200000  860000  348 >,
			< 1344000000  870000  372 >,
			< 1420800000  880000  396 >,
			< 1497600000  890000  421 >,
			< 1574400000  900000  446 >,
			< 1651200000  915000  473 >,
			< 1728000000  930000  501 >,
			< 1804800000  945000  529 >,
			< 1881600000  960000  558 >,
			< 1958400000  975000  588 >,
			< 2035200000  990000  617 >,
			< 2112000000 1005000  649 >,
			< 2150400000 1020000  682 >,
			< 2188800000 1020000  682 >,
			< 2265600000 1035000  716 >,
			< 2342400000 1050000  751 >,
			< 2419200000 1065000  786 >,
			< 2457600000 1070000  802 >;

		qcom,speed3-pvs6-bin-v1 =
			<          0       0    0 >,
			<  300000000  775000   76 >,
			<  345600000  775000   87 >,
			<  422400000  775000  106 >,
			<  499200000  775000  126 >,
			<  576000000  775000  147 >,
			<  652800000  775000  168 >,
			<  729600000  780000  189 >,
			<  806400000  790000  211 >,
			<  883200000  800000  233 >,
			<  960000000  810000  256 >,
			< 1036800000  820000  278 >,
			< 1113600000  830000  301 >,
			< 1190400000  840000  324 >,
			< 1267200000  850000  348 >,
			< 1344000000  860000  372 >,
			< 1420800000  870000  396 >,
			< 1497600000  880000  421 >,
			< 1574400000  890000  446 >,
			< 1651200000  905000  473 >,
			< 1728000000  920000  501 >,
			< 1804800000  935000  529 >,
			< 1881600000  950000  558 >,
			< 1958400000  965000  588 >,
			< 2035200000  980000  617 >,
			< 2112000000  995000  649 >,
			< 2150400000 1010000  682 >,
			< 2188800000 1010000  682 >,
			< 2265600000 1025000  716 >,
			< 2342400000 1040000  751 >,
			< 2419200000 1055000  786 >,
			< 2457600000 1060000  802 >;

		qcom,speed3-pvs7-bin-v1 =
			<          0       0    0 >,
			<  300000000  775000   76 >,
			<  345600000  775000   87 >,
			<  422400000  775000  106 >,
			<  499200000  775000  126 >,
			<  576000000  775000  147 >,
			<  652800000  775000  168 >,
			<  729600000  780000  189 >,
			<  806400000  785000  211 >,
			<  883200000  795000  233 >,
			<  960000000  805000  256 >,
			< 1036800000  815000  278 >,
			< 1113600000  825000  301 >,
			< 1190400000  835000  324 >,
			< 1267200000  845000  348 >,
			< 1344000000  855000  372 >,
			< 1420800000  865000  396 >,
			< 1497600000  875000  421 >,
			< 1574400000  885000  446 >,
			< 1651200000  895000  473 >,
			< 1728000000  910000  501 >,
			< 1804800000  925000  529 >,
			< 1881600000  940000  558 >,
			< 1958400000  955000  588 >,
			< 2035200000  970000  617 >,
			< 2112000000  985000  649 >,
			< 2150400000 1000000  682 >,
			< 2188800000 1000000  682 >,
			< 2265600000 1015000  716 >,
			< 2342400000 1030000  751 >,
			< 2419200000 1045000  786 >,
			< 2457600000 1050000  802 >;

		qcom,speed3-pvs8-bin-v1 =
			<          0       0    0 >,
			<  300000000  775000   76 >,
			<  345600000  775000   87 >,
			<  422400000  775000  106 >,
			<  499200000  775000  126 >,
			<  576000000  775000  147 >,
			<  652800000  775000  168 >,
			<  729600000  775000  189 >,
			<  806400000  780000  211 >,
			<  883200000  785000  233 >,
			<  960000000  795000  256 >,
			< 1036800000  805000  278 >,
			< 1113600000  815000  301 >,
			< 1190400000  825000  324 >,
			< 1267200000  835000  348 >,
			< 1344000000  845000  372 >,
			< 1420800000  855000  396 >,
			< 1497600000  865000  421 >,
			< 1574400000  875000  446 >,
			< 1651200000  885000  473 >,
			< 1728000000  900000  501 >,
			< 1804800000  915000  529 >,
			< 1881600000  930000  558 >,
			< 1958400000  945000  588 >,
			< 2035200000  960000  617 >,
			< 2112000000  975000  649 >,
			< 2150400000  990000  682 >,
			< 2188800000  990000  682 >,
			< 2265600000 1005000  716 >,
			< 2342400000 1020000  751 >,
			< 2419200000 1035000  786 >,
			< 2457600000 1040000  802 >;

		qcom,speed3-pvs9-bin-v1 =
			<          0       0    0 >,
			<  300000000  775000   76 >,
			<  345600000  775000   87 >,
			<  422400000  775000  106 >,
			<  499200000  775000  126 >,
			<  576000000  775000  147 >,
			<  652800000  775000  168 >,
			<  729600000  775000  189 >,
			<  806400000  775000  211 >,
			<  883200000  780000  233 >,
			<  960000000  790000  256 >,
			< 1036800000  800000  278 >,
			< 1113600000  810000  301 >,
			< 1190400000  820000  324 >,
			< 1267200000  830000  348 >,
			< 1344000000  840000  372 >,
			< 1420800000  850000  396 >,
			< 1497600000  860000  421 >,
			< 1574400000  870000  446 >,
			< 1651200000  880000  473 >,
			< 1728000000  890000  501 >,
			< 1804800000  905000  529 >,
			< 1881600000  920000  558 >,
			< 1958400000  935000  588 >,
			< 2035200000  950000  617 >,
			< 2112000000  965000  649 >,
			< 2150400000  980000  682 >,
			< 2188800000  980000  682 >,
			< 2265600000  995000  716 >,
			< 2342400000 1010000  751 >,
			< 2419200000 1025000  786 >,
			< 2457600000 1030000  802 >;

		qcom,speed3-pvs10-bin-v1 =
			<          0       0    0 >,
			<  300000000  775000   76 >,
			<  345600000  775000   87 >,
			<  422400000  775000  106 >,
			<  499200000  775000  126 >,
			<  576000000  775000  147 >,
			<  652800000  775000  168 >,
			<  729600000  775000  189 >,
			<  806400000  775000  211 >,
			<  883200000  780000  233 >,
			<  960000000  785000  256 >,
			< 1036800000  795000  278 >,
			< 1113600000  805000  301 >,
			< 1190400000  815000  324 >,
			< 1267200000  825000  348 >,
			< 1344000000  835000  372 >,
			< 1420800000  845000  396 >,
			< 1497600000  855000  421 >,
			< 1574400000  865000  446 >,
			< 1651200000  875000  473 >,
			< 1728000000  885000  501 >,
			< 1804800000  895000  529 >,
			< 1881600000  910000  558 >,
			< 1958400000  925000  588 >,
			< 2035200000  940000  617 >,
			< 2112000000  955000  649 >,
			< 2150400000  970000  682 >,
			< 2188800000  970000  682 >,
			< 2265600000  980000  716 >,
			< 2342400000  990000  751 >,
			< 2419200000 1015000  786 >,
			< 2457600000 1020000  802 >;

		qcom,speed3-pvs11-bin-v1 =
			<          0       0    0 >,
			<  300000000  775000   76 >,
			<  345600000  775000   87 >,
			<  422400000  775000  106 >,
			<  499200000  775000  126 >,
			<  576000000  775000  147 >,
			<  652800000  775000  168 >,
			<  729600000  775000  189 >,
			<  806400000  775000  211 >,
			<  883200000  775000  233 >,
			<  960000000  780000  256 >,
			< 1036800000  790000  278 >,
			< 1113600000  800000  301 >,
			< 1190400000  810000  324 >,
			< 1267200000  820000  348 >,
			< 1344000000  830000  372 >,
			< 1420800000  840000  396 >,
			< 1497600000  850000  421 >,
			< 1574400000  860000  446 >,
			< 1651200000  870000  473 >,
			< 1728000000  880000  501 >,
			< 1804800000  890000  529 >,
			< 1881600000  900000  558 >,
			< 1958400000  915000  588 >,
			< 2035200000  930000  617 >,
			< 2112000000  945000  649 >,
			< 2150400000  960000  682 >,
			< 2188800000  960000  682 >,
			< 2265600000  975000  716 >,
			< 2342400000  990000  751 >,
			< 2419200000 1005000  786 >,
			< 2457600000 1010000  802 >;

		qcom,speed3-pvs12-bin-v1 =
			<          0       0    0 >,
			<  300000000  775000   76 >,
			<  345600000  775000   87 >,
			<  422400000  775000  106 >,
			<  499200000  775000  126 >,
			<  576000000  775000  147 >,
			<  652800000  775000  168 >,
			<  729600000  775000  189 >,
			<  806400000  775000  211 >,
			<  883200000  775000  233 >,
			<  960000000  780000  256 >,
			< 1036800000  785000  278 >,
			< 1113600000  795000  301 >,
			< 1190400000  805000  324 >,
			< 1267200000  815000  348 >,
			< 1344000000  825000  372 >,
			< 1420800000  835000  396 >,
			< 1497600000  845000  421 >,
			< 1574400000  855000  446 >,
			< 1651200000  865000  473 >,
			< 1728000000  875000  501 >,
			< 1804800000  885000  529 >,
			< 1881600000  895000  558 >,
			< 1958400000  905000  588 >,
			< 2035200000  920000  617 >,
			< 2112000000  935000  649 >,
			< 2150400000  950000  682 >,
			< 2188800000  950000  682 >,
			< 2265600000  965000  716 >,
			< 2342400000  980000  751 >,
			< 2419200000  995000  786 >,
			< 2457600000 1000000  802 >;

		qcom,speed3-pvs13-bin-v1 =
			<          0       0    0 >,
			<  300000000  775000   76 >,
			<  345600000  775000   87 >,
			<  422400000  775000  106 >,
			<  499200000  775000  126 >,
			<  576000000  775000  147 >,
			<  652800000  775000  168 >,
			<  729600000  775000  189 >,
			<  806400000  775000  211 >,
			<  883200000  775000  233 >,
			<  960000000  775000  256 >,
			< 1036800000  780000  278 >,
			< 1113600000  790000  301 >,
			< 1190400000  800000  324 >,
			< 1267200000  810000  348 >,
			< 1344000000  820000  372 >,
			< 1420800000  830000  396 >,
			< 1497600000  840000  421 >,
			< 1574400000  850000  446 >,
			< 1651200000  860000  473 >,
			< 1728000000  870000  501 >,
			< 1804800000  880000  529 >,
			< 1881600000  890000  558 >,
			< 1958400000  900000  588 >,
			< 2035200000  910000  617 >,
			< 2112000000  925000  649 >,
			< 2150400000  940000  682 >,
			< 2188800000  940000  682 >,
			< 2265600000  955000  716 >,
			< 2342400000  970000  751 >,
			< 2419200000  985000  786 >,
			< 2457600000  990000  802 >;

		qcom,speed3-pvs14-bin-v1 =
			<          0       0    0 >,
			<  300000000  750000   76 >,
			<  345600000  750000   87 >,
			<  422400000  750000  106 >,
			<  499200000  750000  126 >,
			<  576000000  750000  147 >,
			<  652800000  750000  168 >,
			<  729600000  750000  189 >,
			<  806400000  750000  211 >,
			<  883200000  755000  233 >,
			<  960000000  765000  256 >,
			< 1036800000  775000  278 >,
			< 1113600000  785000  301 >,
			< 1190400000  795000  324 >,
			< 1267200000  805000  348 >,
			< 1344000000  815000  372 >,
			< 1420800000  825000  396 >,
			< 1497600000  835000  421 >,
			< 1574400000  845000  446 >,
			< 1651200000  855000  473 >,
			< 1728000000  865000  501 >,
			< 1804800000  875000  529 >,
			< 1881600000  885000  558 >,
			< 1958400000  895000  588 >,
			< 2035200000  905000  617 >,
			< 2112000000  915000  649 >,
			< 2150400000  930000  682 >,
			< 2188800000  930000  682 >,
			< 2265600000  945000  716 >,
			< 2342400000  960000  751 >,
			< 2419200000  975000  786 >,
			< 2457600000  980000  802 >;

		qcom,speed3-pvs15-bin-v1 =
			<          0       0    0 >,
			<  300000000  750000   76 >,
			<  345600000  750000   87 >,
			<  422400000  750000  106 >,
			<  499200000  750000  126 >,
			<  576000000  750000  147 >,
			<  652800000  750000  168 >,
			<  729600000  750000  189 >,
			<  806400000  750000  211 >,
			<  883200000  755000  233 >,
			<  960000000  760000  256 >,
			< 1036800000  770000  278 >,
			< 1113600000  780000  301 >,
			< 1190400000  790000  324 >,
			< 1267200000  800000  348 >,
			< 1344000000  810000  372 >,
			< 1420800000  820000  396 >,
			< 1497600000  830000  421 >,
			< 1574400000  840000  446 >,
			< 1651200000  850000  473 >,
			< 1728000000  860000  501 >,
			< 1804800000  870000  529 >,
			< 1881600000  880000  558 >,
			< 1958400000  890000  588 >,
			< 2035200000  900000  617 >,
			< 2112000000  910000  649 >,
			< 2150400000  920000  682 >,
			< 2188800000  920000  682 >,
			< 2265600000  935000  716 >,
			< 2342400000  950000  751 >,
			< 2419200000  965000  786 >,
			< 2457600000  970000  802 >;
	};

	qcom,msm-cpufreq@0 {
		qcom,cpufreq-table =
			<  300000  300000  600 /*  75 MHz */ >,
			<  422400  422400 1200 /* 150 MHz */ >,
			<  652800  499200 1600 /* 200 MHz */ >,
			<  729600  576000 2456 /* 307 MHz */ >,
			<  883200  576000 3680 /* 307 MHz */ >,
			<  960000  960000 4912 /* 460 MHz */ >,
			< 1036800 1036800 6400 /* 460 MHz */ >,
			< 1190400 1190400 6400 /* 460 MHz */ >,
			< 1267200 1267200 6400 /* 614 MHz */ >,
			< 1497600 1497600 7448 /* 614 MHz */ >,
			< 1574400 1574400 7448 /* 800 MHz */ >,
			< 1728000 1728000 7448 /* 800 MHz */ >,
			< 1958400 1958400 7448 /* 931 MHz */ >,
			< 2265600 2265600 7448 /* 931 MHz */ >,
			< 2342400 2265600 7448 /* 931 MHz */ >,
			< 2457600 2265600 7448 /* 931 MHz */ >;
	};
};

/* GPU overrides */
&msm_gpu {
	/* Updated chip ID */
	qcom,chipid = <0x03030001>;

	/* Updated bus bandwidth requirements */
	qcom,msm-bus,vectors-KBps =
		/* Off */
		<26 512 0 0>, <89 604 0 0>,
		/* Sub-SVS / SVS */
		<26 512 0 1600000>, <89 604 0 3200000>,
		/* SVS */
		<26 512 0 2400000>, <89 604 0 3000000>,
		/* Nominal / SVS */
		<26 512 0 4656000>, <89 604 0 3000000>,
		/* Nominal */
		<26 512 0 4656000>, <89 604 0 5120000>,
		/* Turbo / Nominal */
		<26 512 0 7464000>, <89 604 0 5120000>,
		/* Turbo */
		<26 512 0 7464000>, <89 604 0 6400000>;
};

&mdss_mdp {
	qcom,vbif-settings = <0x0004 0x00000001>;

	qcom,mdss-wb-off = <0x00011100 0x00011500
			    0x00011900 0x00011D00 0x00012100>;
	qcom,mdss-intf-off = <0x00012500 0x00012700
			      0x00012900 0x00012b00>;
	qcom,mdss-pingpong-off = <0x00012D00 0x00012E00 0x00012F00>;
	qcom,mdss-has-bwc;
	qcom,mdss-has-decimation;
	qcom,mdss-ad-off = <0x0013100 0x00013300>;
};

&mdss_hdmi_tx {
	reg =	<0xfd922100 0x370>,
		<0xfd922500 0x7C>,
		<0xfc4b8000 0x60F0>;
	reg-names = "core_physical", "phy_physical", "qfprom_physical";
};

&msm_vidc {
	qcom,vidc-ns-map = <0x40000000 0x40000000>;
	qcom,load-freq-tbl = <979200 465000000>,
		<783360 465000000>,
		<489600 266670000>,
		<244800 133330000>;
	qcom,reg-presets = <0x80004 0x1>,
		<0x80070 0x11FFF>,
		<0x80074 0xA4>,
		<0x800A8 0x1FFF>,
		<0x80124 0x3>,
		<0xE0020 0x5555556>,
		<0xE0024 0x0>;
	qcom,bus-ports = <1>;
	qcom,enc-ocmem-ab-ib = <0 0>,
		<138000 1034000>,
		<414000 1034000>,
		<940000 1034000>,
		<1880000 2068000>,
		<3008000 3309000>,
		<3760000 4136000>,
		<4468000 2457000>;
	qcom,dec-ocmem-ab-ib = <0 0>,
		<176000 519000>,
		<456000 519000>,
		<864000 629000>,
		<1728000 1038000>,
		<2766000 1661000>,
		<3456000 2076000>,
		<3662000 2198000>;
	qcom,enc-ddr-ab-ib = <0 0>,
		<120000 302000>,
		<364000 302000>,
		<804000 302000>,
		<1608000 604000>,
		<2576000 967000>,
		<4680000 1404000>,
		<49880000 1496000>;
	qcom,dec-ddr-ab-ib = <0 0>,
		<208000 303000>,
		<536000 303000>,
		<1012000 303000>,
		<2024000 606000>,
		<3240000 970000>,
		<4048000 1212000>,
		<4264000 1279000>;
	qcom,iommu-groups = <&venus_domain_ns &venus_domain_sec_bitstream
			&venus_domain_sec_pixel &venus_domain_sec_non_pixel>;
	qcom,iommu-group-buffer-types = <0xfff 0x91 0x42 0x120>;
	qcom,buffer-type-tz-usage-table = <0x91 0x1>,
					<0x42 0x2>,
					<0x120 0x3>;
};

&krait_pdn {
	qcom,use-phase-switching;
};

&tspp {
	vdd_cx-supply = <&pm8841_s2_corner>;
};
